# EG32M0x register map
Vendor: EGmicro Ltd.; Series: EG32M0x; File version: 1.0
CPU: CM0 r0p0, little endian, no MPU, no FPU, 3 interrupt priority bits
Registers are 32-bit, read-write, reset 0x0 unless marked. A register's access mark holds for its fields unless they carry their own. Offsets are from the block's base; [hi:lo] are bit positions.

## SYSTEM — SYSTEM unit
Base 0x40020000
0x00 SYSKEY reset 0x1
  [31:0] SK — System register write is enabled
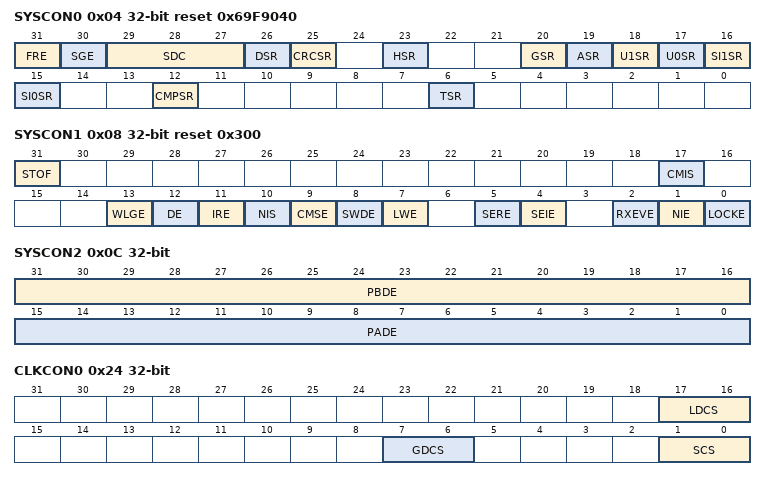
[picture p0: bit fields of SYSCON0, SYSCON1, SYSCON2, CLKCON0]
0x04 SYSCON0 reset 0x69F9040
  [31] FRE — Quick release reset
  [30] SGE — Reset when the system wakes up
  [29:27] SDC — IO wake up delay SLEEP_DLY_CNT system clock cycles
  [26] DSR — IO buffeting circuit software reset control
  [25] CRCSR — CRC computing unit software reset control
  [23] HSR — HWDIV software reset control
  [20] GSR — GPIO related register software reset control
  [19] ASR — ADC related register software reset control
  [18] U1SR — UART1 related register software reset control
  [17] U0SR — UART0 related register software reset control
  [16] SI1SR — SPI_IIC1 related register software reset control
  [15] SI0SR — SPI_IIC0 related register software reset control
  [12] CMPSR — COMP_OPAM related register software reset control
  [6] TSR — TIMER related register software reset control
0x08 SYSCON1 reset 0x300
  [31] STOF — TIMER Output channel Output is enabled
  [17] CMIS — The MCLR function was enabled in CP mode
  [13] WLGE — The watchdog automatically turns off the clock when it enters sleep/stop mode
  [12] DE — DEBUG enable
  [11] IRE — Map interrupt entry from FLASH to SRAM
  [10] NIS — NMI pin polarity reverse selection
  [9] CMSE — Select the system clock in CP mode
  [8] SWDE — SWD Enables the control function
  [7] LWE — LVDVCC wakes up the system in interrupt mode
  [5] SERE — Returns an error signal to the CPU
  [4] SEIE — The NMI interrupt is triggered
  [2] RXEVE — The CPU received events was enabled
  [1] NIE — PB5 triggers the NMI interrupt function
  [0] LOCKE — The system reset is triggered when an out-of-bounds address is accessed twice
0x0C SYSCON2
  [31:16] PBDE — PB antishudder control
  [15:0] PADE — PA antishudder control
0x10 SYSCON3
  [11:0] PCDE — PC antishudder control
0x24 CLKCON0
  [17:16] LDCS — LVD anti-shake clock selection
  [7:6] GDCS — GPIO anti-shake clock selection
  [1:0] SCS — System clock selection
0x28 CLKCON1 reset 0xF8000000
  [5:0] SCD — System clock frequency division
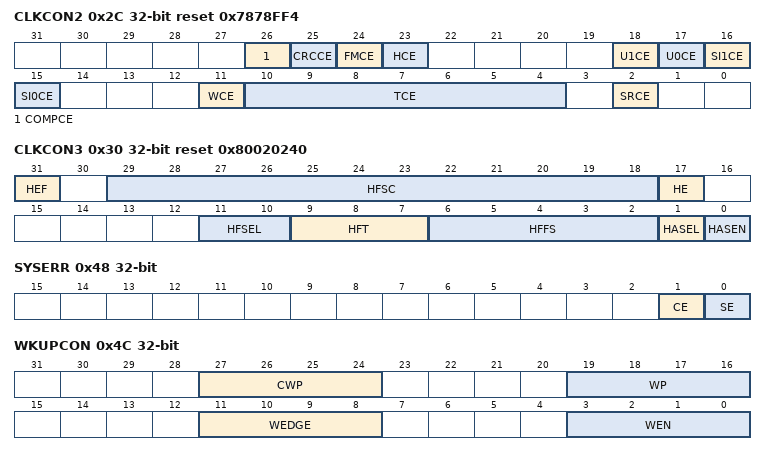
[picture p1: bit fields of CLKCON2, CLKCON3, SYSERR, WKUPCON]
0x2C CLKCON2 reset 0x7878FF4
  [26] COMPCE — The COMP_OPAM clock is enabled
  [25] CRCCE — The CRC clock is enabled
  [24] FMCE — The FLASH erase or write clock function is enabled
  [23] HCE — The HWDIV clock is enabled
  [18] U1CE — The UART1 clock is enabled
  [17] U0CE — The UART0 clock is enabled
  [16] SI1CE — The SPI_IIC1 clock is enabled
  [15] SI0CE — The SPI_IIC0 clock is enabled
  [11] WCE — The WWDG clock is enabled
  [10:4] TCE — The TIMERx clock is enabled
  [2] SRCE — The SRAM0 clock is enabled
0x30 CLKCON3 reset 0x80020240
  [31] HEF — HIRC_CLK Enables the flag bit
  [29:18] HFSC — HIRC_CLK frequency control
  [17] HE — HIRC_CLK Enables control
  [11:10] HFSEL — HIRC frequency selection
  [9:7] HFT — HIRC temperature compensation coefficient
  [6:2] HFFS — HIRC fine tune control
  [1] HASEL — HIRC simulation test selection
  [0] HASEN — Enable HIRC simulation test
0x48 SYSERR
  [1] CE — The clock uses an error flag
  [0] SE — System bus access out of bounds address error flag
0x4C WKUPCON
  [27:24] CWP — Software write 1 Clear WKUP_PEND
  [19:16] WP — IO edge wake up flag
  [11:8] WEDGE — Wake up edge selection
  [3:0] WEN — IO edge detection wakes up
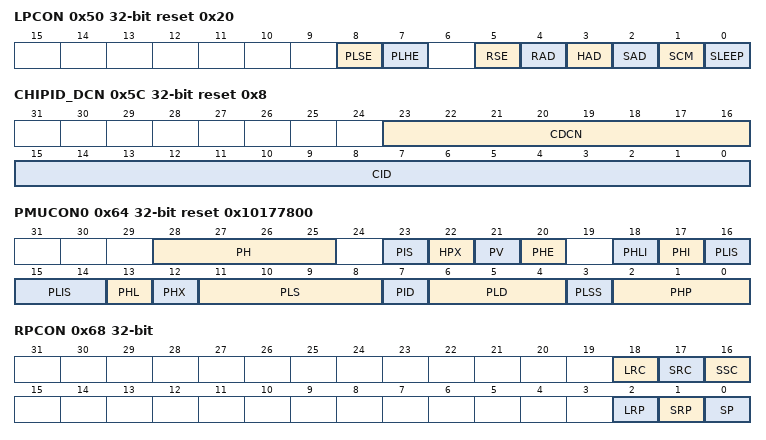
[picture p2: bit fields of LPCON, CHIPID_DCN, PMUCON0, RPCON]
0x50 LPCON reset 0x20
  [8] PLSE — PMU_V2IEN is disabled
  [7] PLHE — The hardware automatically disables PMU_V2IEN
  [5] RSE — LIRC_256K is enabled
  [4] RAD — LIRC_256K is automatically closed when you enter sleep mode
  [3] HAD — HIRC is automatically closed when you enter sleep mode
  [2] SAD — SRAM CE is automatically closed when you enter sleep mode
  [1] SCM — STOP mode
  [0] SLEEP — SLEEP mode
0x5C CHIPID_DCN reset 0x8
  [23:16] CDCN — Record version changes
  [15:0] CID — Chip ID
0x60 MODE
0x64 PMUCON0 reset 0x10177800
  [28:25] PH — Normal mode BG VREF voltage control
  [23] PIS — The internal temperature sensor was enabled
  [22] HPX — Internal LDO configuration options
  [21] PV — VREFMOM Voltage output
  [20] PHE — Analog bias current enabled
  [18] PHLI — VDD LDO weak pull-down resistance switch
  [17] PHI — VDD LDO pulldown resistance switch
  [16:14] PLIS — Low power reference current control
  [13] PHL — The LDO function in common mode is enabled
  [12] PHX — Internal LDO was enabled
  [11:8] PLS — ULPBG VREF voltage control
  [7] PID — Deep sleep current switch
  [6:4] PLD — Low power mode LDO voltage selection
  [3] PLSS — PMU low power acceleration
  [2:0] PHP — Normal mode LDO voltage selection
0x68 RPCON
  [18] LRC — Software Write 1 Clear LOCK_RESET_PEND
  [17] SRC — Software Write 1 Clear SOFT_RESET_PEND
  [16] SSC — Software Write 1 Clear SLEEP_PEND
  [2] LRP — The CPU LOCK RESET flag bit occurs
  [1] SRP — The software writes 1 to the bit to trigger the system reset
  [0] SP — Enter the sleep mode flag bit
0x6C PMU_BK reset 0x10
  [6:4] PL — Low power mode LDO voltage tap selection
